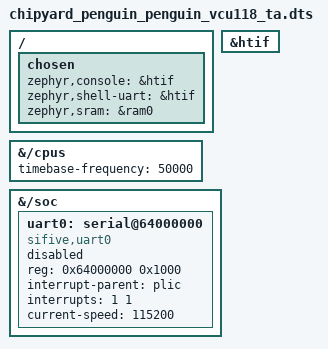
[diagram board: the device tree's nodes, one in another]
/*
 * SPDX-License-Identifier: Apache-2.0
 *
 * Variant "vcu118_ta": the real Penguin RTL (EE290SimConfig) on a VCU118,
 * exactly as the TA built it: EE290VCU118Config in bringup-chipyard commit
 * 245f2a9d, fpga/src/main/scala/vcu118/Configs.scala:85-91:
 *   WithoutSDIO ++ WithVCU118PeripheralUARTOnPMOD ++ WithFPGAFrequency(50)
 *     ++ WithVCU118Tweaks ++ EE290SimConfig
 * (cited below as TA:Configs.scala:<line>; read with
 *  git -C $BRINGUP_CHIPYARD show origin/main:fpga/src/main/scala/vcu118/Configs.scala)
 *
 * Difference to the existing "vcu118" variant (generic Chipyard VCU118 flow:
 * sdboot + UART console + 1 MHz mtime): this one keeps the HTIF console that
 * the base board uses, because the TA loads over UART-TSI and the console is
 * proxied by the TSI host (WithVCU118UARTTSI, Configs.scala:51, plus
 * testchipip.tsi.WithUARTTSIClient, Configs.scala:58). Only three things
 * differ from the base board: the clock (50 kHz mtime), the peripheral UART
 * (moved to 0x6400_0000, off by default) and the DRAM size.
 *
 * VERIFIED against the DTS Chipyard generated for this exact config
 * (`make SUB_PROJECT=vcu118 CONFIG=EE290VCU118Config verilog`, bringup-chipyard
 * 245f2a9d, the TA Nicolas Rakela Herrera's config, 2026-10-09). Cited below as
 * GEN:<line>, where GEN is
 *   $BRINGUP_CHIPYARD/fpga/generated-src/chipyard.fpga.vcu118.
 *   VCU118FPGATestHarness.EE290VCU118Config/<same name>.dts
 * (generated by building that config; not kept in this repo).
 * Confirmed: timebase 50 kHz (GEN:17,38), every bus clock 50 MHz (GEN:65-129),
 * riscv,isa identical to penguin.dtsi (GEN:36), PLIC ndev 1 / max-priority 1 /
 * contexts M=11,S=9 (GEN:98-107), CLINT (GEN:71-76), UART at 0x64000000 with
 * PLIC source 1 (GEN:131-138). Chipyard emits no node for the Atlas NPU; its
 * windows are confirmed from the elaboration graph instead (see atlas below).
 */

#include <chipyard/penguin.dtsi>

/* Console = HTIF through the TSI host, like the base board (base DTS). */
/ {
	chosen {
		zephyr,console = &htif;
		zephyr,shell-uart = &htif;
		zephyr,sram = &ram0;
	};
};

&htif {
	status = "okay";
};

/* mtime / timebase = 50 kHz. WithFPGAFrequency(50) (TA:Configs.scala:88,112-119)
 * includes WithPeripheryBusFrequency(50), which sets WithTimebase(50 * 1e3)
 * (bringup-chipyard generators/chipyard/.../ClockingFragments.scala:92-93).
 * It is leftmost of the timebase setters, so it beats WithSystemModifications'
 * DTSTimebase = 1e6 (TA:Configs.scala:31) and EE290BaseConfig's 500 MHz.
 * RTC divider = PBUS 50 MHz / 50 kHz = 1000 (rocket-chip subsystem/RTC.scala:20-21).
 * Must equal CONFIG_SYS_CLOCK_HW_CYCLES_PER_SEC (soc Kconfig.defconfig keys
 * this off CONFIG_CHIPYARD_FPGA_TA).
 */
&{/cpus} {
	timebase-frequency = <50000>;
};

/* Peripheral UART. The chip has it at 0x1002_0000; the TA re-adds it at
 * 0x6400_0000 (TA:Configs.scala:69, UARTParams(address = 0x64000000)),
 * routed to PMOD J52: chip RX = AT16, chip TX = AV15, LVCMOS18, pull-up on RX
 * (TA HarnessBinders.scala:45-56). Attached to the PBUS (rocket-chip-blocks
 * UART.scala:261 controlWhere = PBUS), compatible "sifive,uart0" (UART.scala:111),
 * one interrupt (UART.scala:118, nInterrupts = 1 + includeParity), default
 * initBaudRate 115200 (UART.scala:64), reset divisor = PBUS 50 MHz / 115200
 * = 434 (UART.scala:269). PLIC source 1: it is the only interrupt device
 * (WithNExtTopInterrupts(0), AbstractConfig.scala:105; the TA's SPI is dropped
 * by WithoutSDIO, Configs.scala:97-100). CONFIRMED by GEN:131-138 (serial@64000000,
 * interrupt-parent = PLIC, interrupts = <1>, clocks = pbus_clock) and
 * GEN:125-129,114-119 (pbus_clock = 50000000, so the UART clock is 50 MHz).
 *
 * status = "disabled": the console is HTIF, so nothing needs this UART, and
 * on a bitstream without the PMOD cable attached it would only add risk. Set
 * status = "okay" and CONFIG_UART_SIFIVE_PORT_0=y in an app overlay/conf to
 * use it as a second serial port; its clock is 50 MHz (soc.h: 50 kHz * 1000).
 */
/delete-node/ &uart0;

&{/soc} {
	uart0: serial@64000000 {
		compatible = "sifive,uart0";
		reg = <0x64000000 0x1000>;
		reg-names = "control";
		interrupt-parent = <&plic>;
		interrupts = <1 1>;	/* PLIC source 1 (GEN:136), priority 1 (PLIC max, GEN:105) */
		current-speed = <115200>;
		status = "disabled";
	};
};

/* DRAM. The board really has 2 GiB at 0x8000_0000: ExtMem size =
 * VCU118DDRSize (TA:Configs.scala:39), 0x40000000 * 2 in fpga-shells
 * VCU118NewShell.scala:305 (SerialTL removed, TA:Configs.scala:40).
 * CONFIRMED by the generated DTS: memory@80000000 reg = <0x80000000 0x80000000>
 * (GEN:52-55), also memmap.json (base 2147483648, size 2147483648).
 * ram0 deliberately stays at 256 MiB, as on the base board: that is all
 * Zephyr needs, and Atlas test buffers live at 0x9000_0000 (the end of ram0,
 * see penguin.dtsi); if ram0 covered all 2 GiB the libc heap / linker could
 * grow into them. Raise reg to <0x80000000 0x80000000> only for an app that
 * needs the memory and does not use those buffers.
 */

/* Atlas NPU (node `atlas` in penguin.dtsi). Chipyard emits no DTS node and no
 * memmap.json entry for it, but the elaboration graph
 * (<config>.chiptop0.graphml, bringup-chipyard 245f2a9d) lists the three
 * windows of atlasTile, identical to penguin.dtsi:
 *   vmem  AddressSet(0x20000000,0xfffff) + (0x20100000,0x7ffff) = 1.5 MiB  (graphml:10090)
 *   imem  AddressSet(0x20000,0x1ffff) = 128 KiB                             (graphml:10174)
 *   csr   AddressSet(0x40000,0xfff)   = 4 KiB                               (graphml:10187)
 * The scratchpad memory@8000000 (64 KiB) is in the generated DTS but marked
 * status = "disabled" (GEN:47-51), Chipyard's way of hiding it from Linux; it
 * is still a real, coherent, executable region in memmap.json, so spad0 in
 * penguin.dtsi stays as it is.
 */
